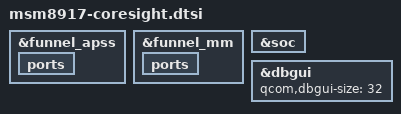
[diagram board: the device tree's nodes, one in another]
#include "msm8937-coresight.dtsi"

&funnel_apss {
	ports {
		/delete-node/ port@1;
		/delete-node/ port@2;
		/delete-node/ port@3;
		/delete-node/ port@4;
	};
};

&funnel_mm {
	ports {
		/delete-node/ port@4;
	};
};

&soc {
	/delete-node/ etm@619c000;
	/delete-node/ etm@619d000;
	/delete-node/ etm@619e000;
	/delete-node/ etm@619f000;
	/delete-node/ cti@6198000;
	/delete-node/ cti@6199000;
	/delete-node/ cti@619a000;
	/delete-node/ cti@619b000;
};

&dbgui {
	qcom,dbgui-size = <32>;
};
